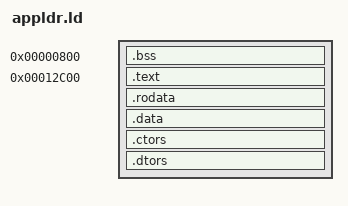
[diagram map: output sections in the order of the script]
ENTRY(_start)

SECTIONS
{
  . = 0x800;

  .bss :
  {
    */appldr/src/loader_global.o(.bss.g_loader)
    */appldr/src/loader.o(.bss.s_unwrapped_keysets)
    */appldr/src/loader.o(.bss.s_unwrapped_keys)
    */appldr/src/loader.o(.bss.s_version)
    */appldr/src/loader.o(.bss.s_version_checked)
    */appldr/src/loader_data.o(.bss.g_qa_flag)
    */appldr/src/loader_data.o(.bss.g_key)
    */appldr/src/loader_data.o(.bss.g_iv)
    */appldr/src/loader_data.o(.bss.g_9b0)
    */appldr/src/loader_data.o(.bss.g_auth_area)
    */appldr/src/loader_data.o(.bss.g_qa_token)
    */appldr/src/loader_data.o(.bss.g_revoke_list)
    */appldr/src/loader_data.o(.bss.g_stream_area)
    */appldr/src/loader_data.o(.bss.g_direct_area)
    */isoldr/src/cipher_aes256_cbc.o(.bss.g_aes256_cbc)
    */isoldr/src/verifier_ecdsa.o(.bss.verify_hash)
    */appldr/src/auth_data.o(.bss.g_revoke_buf)
    */appldr/src/auth_data.o(.bss.g_revoke_digest)
    */lv1ldr/src/auth_buffers.o(.bss.g_part_area)
    */lv1ldr/src/auth_buffers.o(.bss.g_part_digest)
    */appldr/src/auth_data.o(.bss.g_3e40)
    */lv1ldr/src/auth_transfer.o(.bss.g_inf_tail)
    */isoldr/src/hmac_digest.o(.bss.g_hmac)
    */lv1ldr/src/auth_transfer.o(.bss.g_inf_offset)
    */lv1ldr/src/auth_transfer.o(.bss.g_inf_total)
    */lv1ldr/src/auth_transfer.o(.bss.g_inf_out)
    */lv1ldr/src/auth_transfer.o(.bss.g_inf_done)
    */lv1ldr/src/auth_transfer.o(.bss.g_inf_avail)
    */lv1ldr/src/auth_transfer.o(.bss.g_inf_p)
    */appldr/src/mac_aes_cmac.o(.bss.g_mac_aes_cmac)
    */appldr/src/mac_hmac_sha1.o(.bss.g_mac_hmac_sha1)
    */appldr/src/mac_type1.o(.bss.g_mac_type1)
    */appldr/src/cipher_aes128_cbc_chain.o(.bss.g_aes128_cbc_chain)
    */isoldr/src/cipher_aes128_ctr.o(.bss.g_aes128_ctr)
    */appldr/src/cipher_plain.o(.bss.g_plain_cipher)
    */isoldr/src/dma_buffer.o(.bss.g_dma_mfc)
    */lv1ldr/zlib/lv1ldr_inflate.o(.bss.g_strm)
    */lv1ldr/zlib/inflate.o(.bss.lv1ldr_window_used)
    */lv1ldr/zlib/inflate.o(.bss.lv1ldr_state_used)
    */lv1ldr/zlib/inflate.o(.bss.lv1ldr_state)
    */lv1ldr/zlib/inflate.o(.bss.lv1ldr_window)
    *(.bss .bss.* .gnu.linkonce.b.*)
    *(COMMON)
  }

  . = 0x12c00;

  .text :
  {
    */isoldr/src/crt0.o(.text)
    *(.text._ZN6cipher6vslot6EPKv)
    *(.text._ZN6cipher6vslot7EPv)
    *(.text._ZN3mac7restoreEPKv)
    *(.text._ZN3mac4saveEPv)
    *(.text._ZN3mac12set_mac_sizeEj)
    */appldr/src/mac_hmac_sha1.o(.text._ZN13mac_hmac_sha112set_mac_sizeEj)
    *(.text._ZN3macD0Ev)
    *(.text._ZN3macD1Ev)
    *(.text._ZN3macD2Ev)
    */appldr/src/mac_type1.o(.text._ZN9mac_type1D0Ev)
    */appldr/src/mac_type1.o(.text._ZN9mac_type1D1Ev)
    */appldr/src/mac_hmac_sha1.o(.text._ZN13mac_hmac_sha1D0Ev)
    */appldr/src/mac_hmac_sha1.o(.text._ZN13mac_hmac_sha1D1Ev)
    */appldr/src/mac_aes_cmac.o(.text._ZN12mac_aes_cmacD0Ev)
    */appldr/src/mac_aes_cmac.o(.text._ZN12mac_aes_cmacD1Ev)
    *(.text._ZN6cipherD0Ev)
    *(.text._ZN6cipherD1Ev)
    */appldr/src/loader_global.o(.text._Z41__static_initialization_and_destruction_0ii)
    */appldr/src/loader_global.o(.text._GLOBAL__I_g_loader)
    */appldr/src/main.o(.text._Z9stop_withl)
    */appldr/src/main.o(.text.main)
    */lv2ldr/src/auth_checks.o(.text._ZeqRK10auth_flagsS1_)
    */appldr/src/auth_flags.o(.text._ZneRK10auth_flagsS1_)
    */lv2ldr/src/auth_checks.o(.text._ZanRK10auth_flagsS1_)
    */lv2ldr/src/hash_reader.o(.text._Z12bytes_differPKhS0_i)
    */appldr/src/loader.o(.text._ZN6loader14version_numberEy)
    */appldr/src/loader.o(.text._ZN6loader9has_flagsERK10auth_flagsS2_)
    */appldr/src/loader.o(.text._ZN6loader9read_modeEv)
    */appldr/src/loader.o(.text._ZN6loader14override_stateEP10auth_flags)
    */appldr/src/loader.o(.text._ZN6loader14check_type_bitEjPK10auth_flags)
    */appldr/src/loader.o(.text._ZN6loader18keyset_pub_is_zeroEv)
    */appldr/src/loader.o(.text._ZN6loader13check_flags_aEyRK10auth_flagsS2_)
    */appldr/src/loader.o(.text._ZN6loader9is_kind_bEPK13auth_app_infoRK10auth_flagsS5_)
    */appldr/src/loader.o(.text._ZN6loader9is_kind_cEPK13auth_app_infoRK10auth_flagsS5_)
    */appldr/src/loader.o(.text._ZN6loader9is_kind_dEPK13auth_app_infoRK10auth_flagsS5_)
    */appldr/src/loader.o(.text._ZN6loader7unpack3EPKjP10auth_flags)
    */appldr/src/loader.o(.text._ZN6loader7unpack4EPKjP10auth_flags)
    */appldr/src/loader.o(.text._ZN6loader11check_knownERK10auth_flagsS2_PKh)
    */appldr/src/loader.o(.text._ZN6loader8flag_setEv)
    */appldr/src/loader.o(.text._ZN6loader16check_type_valueEjj)
    */appldr/src/loader.o(.text._ZN6loader8lookup_aEtPj)
    */appldr/src/loader.o(.text._ZN6loader8lookup_bEtPj)
    */appldr/src/loader.o(.text._ZN6loader6lookupEjtPj)
    */appldr/src/loader.o(.text._ZN6loader10is_129_130Ejb)
    */appldr/src/loader.o(.text._ZN9key_storeD0Ev)
    */appldr/src/loader.o(.text._ZN9key_storeD1Ev)
    *(.text._ZN9encryptorD0Ev)
    *(.text._ZN9encryptorD1Ev)
    *(.text._ZN9encryptorD2Ev)
    */isoldr/src/aes256_cbc_encryptor.o(.text._ZN20aes256_cbc_encryptorD0Ev)
    *(.text._ZN20aes256_cbc_encryptorD1Ev)
    */appldr/src/segment_loader.o(.text._ZN14segment_loaderD0Ev)
    */appldr/src/segment_loader.o(.text._ZN14segment_loaderD1Ev)
    */appldr/src/loader.o(.text._ZN9key_store7requestEv)
    */appldr/src/loader.o(.text._ZN9key_store11unwrap_keysEv)
    */appldr/src/loader.o(.text._ZN9key_store14unwrap_keysetsEv)
    */appldr/src/loader.o(.text._ZN9key_store13check_versionEy)
    */appldr/src/loader.o(.text._ZN6loader17check_old_versionEP13authenticator)
    */appldr/src/loader.o(.text._ZN6loader5fetchEyPv)
    */appldr/src/loader.o(.text._ZN6loader12read_requestEv)
    */appldr/src/loader.o(.text._ZN6loader10put_resultEv)
    */appldr/src/loader.o(.text._ZN6loader10get_digestEPhj)
    */appldr/src/loader.o(.text._ZN6loader19check_version_limitEyP13authenticator)
    *(.text._ZN17tagged_dma_bufferD1Ev)
    */appldr/src/loader.o(.text._ZN6loader10check_hashEv)
    */appldr/src/loader.o(.text._ZN6loader20check_control_digestEP13authenticator)
    */appldr/src/loader.o(.text._ZN6loader9get_stateEP13authenticatorP10auth_flags)
    */appldr/src/loader.o(.text._ZN6loader10put_answerEP13authenticatorPK8app_args)
    */appldr/src/loader.o(.text._ZN6loader10check_kindEv)
    */appldr/src/loader.o(.text._ZN6loader11check_stateEjP13authenticatorP10auth_flags)
    */appldr/src/loader.o(.text._ZN6loader12decrypt_argsEPKh)
    */appldr/src/loader.o(.text._ZN6loader13pick_args_keyEtbP10keyset_ref)
    */appldr/src/loader.o(.text._ZN6loader11find_keysetEjjtjbP10keyset_ref)
    */appldr/src/loader.o(.text._ZN6loader12read_qa_flagEjPKhPK8qa_tokenPhS5_)
    */appldr/src/loader.o(.text._ZN6loader11open_paramsEPjPh)
    */appldr/src/loader.o(.text._ZN6loader6load_bEv)
    */appldr/src/loader.o(.text._ZN6loader9read_typeEPjP13authenticator)
    */appldr/src/loader.o(.text._ZN6loader14section_extentEjjPyS0_)
    */appldr/src/loader.o(.text._ZN6loader12load_sectionEv)
    */appldr/src/loader.o(.text._ZN6loader17check_revoke_listEP11revoke_listPKv)
    */appldr/src/loader.o(.text._ZN6loader7prepareEv)
    */appldr/src/loader.o(.text._ZN6loader10load_imageEjP13authenticatorPK10keyset_refj)
    */appldr/src/loader.o(.text._ZN6loader13check_revokedEjP11revoke_listP13authenticator)
    */appldr/src/loader.o(.text._ZN6loader11check_imageEv)
    */appldr/src/loader.o(.text._ZN6loader5resetEv)
    */appldr/src/loader.o(.text._ZN6loader10open_imageEv)
    */appldr/src/loader.o(.text._ZN6loader6load_aEv)
    */appldr/src/loader.o(.text._ZN6loaderC1Ev)
    */appldr/src/loader.o(.text._ZN6loaderC2Ev)
    */appldr/src/loader.o(.text._ZN6loader3runEv)
    */isoldr/src/hmac_digest.o(.text._ZN11hmac_digestC2Ev)
    */isoldr/src/hmac_digest.o(.text._ZN11hmac_digestC1Ev)
    */isoldr/src/qa_flag.o(.text._ZN14qa_flag_reader4initEv)
    *(.text._ZN6cipherD2Ev)
    */isoldr/src/cipher_aes256_cbc.o(.text._ZN17aes256_cbc_cipherD0Ev)
    *(.text._ZN17aes256_cbc_cipherD1Ev)
    *(.text._ZN8verifierD0Ev)
    *(.text._ZN8verifierD1Ev)
    *(.text._ZN8verifierD2Ev)
    */isoldr/src/verifier_ecdsa.o(.text._ZN14ecdsa_verifierD0Ev)
    *(.text._ZN14ecdsa_verifierD1Ev)
    */isoldr/src/qa_flag.o(.text._ZN14qa_flag_reader5checkEjPKhPhS1_S1_)
    */appldr/src/segment_loader.o(.text._ZN13direct_loaderC1Ev)
    */appldr/src/segment_loader.o(.text._ZN13direct_loaderC2Ev)
    */appldr/src/segment_loader.o(.text._ZN13direct_loader4openEP13authenticatorj)
    */appldr/src/segment_loader.o(.text._ZN13direct_loader5closeEv)
    */appldr/src/segment_loader.o(.text._ZN14segment_loaderD2Ev)
    */appldr/src/segment_loader.o(.text._ZN13direct_loaderD0Ev)
    */appldr/src/segment_loader.o(.text._ZN13direct_loaderD1Ev)
    */appldr/src/segment_loader.o(.text._ZN13direct_loader4loadEyyyyPP10dma_bufferjS2_j)
    */appldr/src/segment_loader.o(.text._ZN13stream_loaderC1Ev)
    */appldr/src/segment_loader.o(.text._ZN13stream_loaderC2Ev)
    */appldr/src/segment_loader.o(.text._ZN13stream_loader4openEP13authenticatorj)
    */appldr/src/segment_loader.o(.text._ZN13stream_loader5closeEv)
    */appldr/src/segment_loader.o(.text._ZN13stream_loaderD0Ev)
    */appldr/src/segment_loader.o(.text._ZN13stream_loaderD1Ev)
    */appldr/src/segment_loader.o(.text._ZN13stream_loader6notifyEj)
    */appldr/src/segment_loader.o(.text._ZN13stream_loader10wait_readyEv)
    */appldr/src/segment_loader.o(.text._ZN13stream_loader10next_blockEP12stream_block)
    */appldr/src/segment_loader.o(.text._ZN13stream_loader4loadEyyyyPP10dma_bufferjS2_j)
    */appldr/src/hash_verify.o(.text._ZN11hash_reader6verifyEPKhj)
    */lv2ldr/src/hash_reader.o(.text._ZN11hash_reader4openEyyPP10dma_bufferjPKhj)
    *(.text._ZN11hash_readerD0Ev)
    *(.text._ZN11hash_readerD1Ev)
    */lv2ldr/src/hash_reader.o(.text._ZN11hash_readerC1Ev)
    */lv2ldr/src/hash_reader.o(.text._ZN11hash_readerC2Ev)
    */lv2ldr/src/hash_reader.o(.text._ZN11hash_reader4readEv)
    *(.text._ZN17aes256_cbc_cipherC1Ev)
    */isoldr/src/cipher_aes256_cbc.o(.text._Z41__static_initialization_and_destruction_0ii)
    */isoldr/src/cipher_aes256_cbc.o(.text._GLOBAL__D_g_aes256_cbc)
    */isoldr/src/cipher_aes256_cbc.o(.text._GLOBAL__I_g_aes256_cbc)
    */isoldr/src/cipher_aes256_cbc.o(.text._ZN17aes256_cbc_cipher7decryptEPKviPv)
    */isoldr/src/cipher_aes256_cbc.o(.text._ZN17aes256_cbc_cipher7set_keyEPKhS1_)
    */appldr/src/loader.o(.text._ZN20aes256_cbc_encryptorC1Ev)
    */isoldr/src/aes256_cbc_encryptor.o(.text._ZN20aes256_cbc_encryptor7set_keyEPKhPK9cipher_iv)
    */isoldr/src/aes256_cbc_encryptor.o(.text._ZN20aes256_cbc_encryptor7encryptEPKviPv)
    */lv2ldr/src/auth_checks.o(.text._ZN13authenticator19check_auth_id_classEyy)
    */lv2ldr/src/auth_checks.o(.text._ZN13authenticator18has_required_flagsEv)
    */lv2ldr/src/auth_checks.o(.text._ZN13authenticator12check_issuerEyy)
    */appldr/src/auth_app.o(.text._ZN13authenticator10set_headerEjPKv)
    */lv1ldr/src/auth_buffers.o(.text._ZN13authenticator17check_part_digestEPK12auth_section)
    */appldr/src/auth_app_checks.o(.text._ZN13authenticator20check_section_digestEv)
    */isoldr/src/verifier_ecdsa.o(.text._ZN14ecdsa_verifier6verifyEPKhiS1_)
    */isoldr/src/verifier_ecdsa.o(.text._ZN14ecdsa_verifierC1EPKhj)
    */isoldr/src/verifier_ecdsa.o(.text._ZN14ecdsa_verifierC2EPKhj)
    */lv2ldr/src/auth_checks.o(.text._ZN13authenticator9get_stateEPy)
    */lv2ldr/src/auth_checks.o(.text._ZN13authenticator12get_app_infoEP13auth_app_info)
    */appldr/src/auth_app_checks.o(.text._ZN13authenticator16get_section_infoEjPv)
    */appldr/src/auth_app_checks.o(.text._ZN13authenticator18get_control_digestEPh)
    */lv1ldr/src/loader_params.o(.text._ZN11param_block4initEv)
    */lv1ldr/src/loader_params.o(.text._ZN11param_block4openEPKhjS1_S1_S1_S1_PjPhS3_)
    */appldr/src/auth_app_checks.o(.text._ZN13authenticator8is_elf64Ev)
    */appldr/src/auth_app_checks.o(.text._ZN13authenticator8is_elf32Ev)
    */appldr/src/auth_app_checks.o(.text._ZN13authenticator8flag_1b9Ev)
    */lv2ldr/src/auth_checks.o(.text._ZN10auth_state3getEPy)
    */lv1ldr/src/auth_buffers.o(.text._ZN10auth_state4loadEPK10auth_entryy)
    */lv1ldr/src/auth_buffers.o(.text._ZN10auth_stateC1Ev)
    */lv1ldr/src/auth_buffers.o(.text._ZN10auth_stateC2Ev)
    */lv2ldr/src/revoke_list.o(.text._ZN11revoke_list4initEv)
    */lv2ldr/src/revoke_list.o(.text._ZN11revoke_list12check_headerEPK18revoke_list_header)
    */lv2ldr/src/revoke_list.o(.text._ZN11revoke_list13check_versionEy)
    */isoldr/src/cipher_aes128_ctr.o(.text._ZN17aes128_ctr_cipherD0Ev)
    */isoldr/src/cipher_aes128_ctr.o(.text._ZN17aes128_ctr_cipherD1Ev)
    */lv2ldr/src/revoke_list.o(.text._ZN11revoke_list15check_encryptedEPK12auth_section)
    */lv2ldr/src/revoke_list.o(.text._ZN11revoke_list11check_plainEPK12auth_section)
    */lv2ldr/src/revoke_list.o(.text._ZN11revoke_list5parseEv)
    */lv2ldr/src/revoke_list.o(.text._ZN11revoke_list4openEPKhS1_S1_PKj)
    */lv2ldr/src/revoke_list.o(.text._ZN11revoke_list4loadEPKv)
    */lv1ldr/src/authenticator.o(.text._ZN9elf_imageC1Ev)
    */lv1ldr/src/authenticator.o(.text._ZN9elf_image4loadEPKv)
    */lv1ldr/src/authenticator.o(.text._ZN13authenticator10set_offsetEy)
    */lv1ldr/src/authenticator.o(.text._ZN13authenticator14check_app_infoEPK13auth_app_infoj)
    */lv1ldr/src/authenticator.o(.text._ZN13authenticator9check_appEP9sce_imagej)
    */lv1ldr/src/authenticator.o(.text._ZN13authenticator11clear_partsEv)
    */lv1ldr/src/authenticator.o(.text._ZN13authenticatorC1Ev)
    */lv1ldr/src/authenticator.o(.text._ZN13authenticatorC2Ev)
    */appldr/src/auth_app.o(.text._ZN13authenticator5resetEv)
    */lv1ldr/src/authenticator.o(.text._ZN13authenticator19read_program_headerEjP10Elf64_Phdr)
    */lv1ldr/src/authenticator.o(.text._ZN13authenticator15read_elf_headerEP10Elf64_Ehdr)
    */isoldr/src/elf_reader32.o(.text._ZN13authenticator19read_program_headerEjP10Elf32_Phdr)
    */isoldr/src/elf_reader32.o(.text._ZN13authenticator15read_elf_headerEP10Elf32_Ehdr)
    */appldr/src/auth_app.o(.text._ZN13authenticator14select_sectionEjj)
    */appldr/src/auth_app.o(.text._ZN10auth_block5get_wEPy)
    */appldr/src/auth_app.o(.text._ZN10auth_block10get_digestEPh)
    */lv1ldr/src/authenticator.o(.text._ZN10auth_block3getEPy)
    */lv1ldr/src/auth_buffers.o(.text._ZN10auth_block4loadEPK10auth_entryy)
    */lv1ldr/src/auth_buffers.o(.text._ZN10auth_blockC1Ev)
    */lv1ldr/src/auth_buffers.o(.text._ZN10auth_blockC2Ev)
    */isoldr/src/hmac_digest.o(.text._Z41__static_initialization_and_destruction_0ii)
    */isoldr/src/hmac_digest.o(.text._GLOBAL__I_g_hmac)
    */isoldr/src/hmac_digest.o(.text._GLOBAL__D_g_hmac)
    */isoldr/src/hmac_digest.o(.text._ZN11hmac_digest6updateEPKhi)
    */isoldr/src/hmac_digest.o(.text._ZN11hmac_digest5finalEPh)
    */isoldr/src/hmac_digest.o(.text._ZN11hmac_digest4initEPKhj)
    */isoldr/src/hmac_digest.o(.text._ZN11hmac_digest6digestEPKhiPhS1_j)
    */lv2ldr/src/revoke_check.o(.text._ZN11revoke_list10is_revokedEjyy)
    */appldr/src/cipher_aes128_cbc_chain.o(.text._ZN23aes128_cbc_chain_cipherD0Ev)
    */appldr/src/cipher_aes128_cbc_chain.o(.text._ZN23aes128_cbc_chain_cipherD1Ev)
    */appldr/src/auth_app.o(.text._ZN13authenticator11load_headerEjPKhS1_S1_PKjPP10dma_bufferjPvS1_b)
    */appldr/src/auth_app.o(.text._ZN11header_data7decryptEv)
    */lv1ldr/src/auth_buffers.o(.text._ZN11header_data5clearEv)
    */appldr/src/auth_app.o(.text._ZN9auth_tail5resetEv)
    */lv1ldr/src/auth_buffers.o(.text._ZN9auth_tailC1Ev)
    */lv1ldr/src/auth_buffers.o(.text._ZN9auth_tailC2Ev)
    */appldr/src/auth_app.o(.text._ZN11header_data4hashEv)
    */appldr/src/auth_app.o(.text._ZN11header_data7restoreEPK10dma_buffer)
    */appldr/src/auth_app.o(.text._ZN11header_data7prependEPK10dma_bufferj)
    */appldr/src/auth_app.o(.text._ZN11header_data4saveEPK10dma_buffer)
    */appldr/src/auth_app_transfer.o(.text._ZN13authenticator16transfer_segmentEyyyyPP10dma_bufferjS2_jPy)
    */appldr/src/auth_app_transfer.o(.text._ZN13authenticator17transfer_deflatedEybbPy)
    */appldr/src/auth_app_transfer.o(.text._ZN13authenticator15transfer_storedEbbPy)
    */lv1ldr/src/auth_transfer.o(.text._ZN13authenticator13inflate_pieceEP10dma_bufferyPy)
    */appldr/src/auth_app_transfer.o(.text._ZN13authenticator7requeueEP10dma_bufferS1_RKbS3_Py)
    */appldr/src/data_decryptor.o(.text._ZN14data_decryptor5resetEv)
    */appldr/src/data_decryptor.o(.text._ZN14data_decryptor10set_cipherEj)
    */appldr/src/data_decryptor.o(.text._ZN14data_decryptor7set_macEj)
    */appldr/src/data_decryptor.o(.text._ZN14data_decryptor5checkEjjj)
    */appldr/src/data_decryptor.o(.text._ZN14data_decryptor7restoreEPK15decryptor_state)
    */appldr/src/cipher_plain.o(.text._ZN12plain_cipherD0Ev)
    */appldr/src/cipher_plain.o(.text._ZN12plain_cipherD1Ev)
    */appldr/src/data_decryptor.o(.text._ZN14data_decryptor4saveEP15decryptor_state)
    */appldr/src/data_decryptor.o(.text._ZN14data_decryptor14derive_mac_keyEPKhPhjj)
    */appldr/src/data_decryptor.o(.text._ZN14data_decryptor10derive_keyEPKhS1_PhS2_jj)
    */appldr/src/data_decryptor.o(.text._ZN14data_decryptor10state_keysEPhS0_)
    */appldr/src/data_decryptor.o(.text._ZN14data_decryptor4sealEPh)
    */appldr/src/data_decryptor.o(.text._ZN14data_decryptor6unsealEPh)
    */appldr/src/data_decryptor.o(.text._ZN14data_decryptor9put_stateEyPKh)
    */appldr/src/data_decryptor.o(.text._ZN14data_decryptor9get_stateEyPh)
    */appldr/src/data_decryptor.o(.text._ZN14data_decryptor6finishEyy)
    */appldr/src/data_decryptor.o(.text._ZN14data_decryptor4pumpEv)
    */appldr/src/data_decryptor.o(.text._ZN14data_decryptor7processEyyyPP10dma_bufferjS2_j)
    */appldr/src/data_decryptor.o(.text._ZN14data_decryptorC1Ev)
    */appldr/src/data_decryptor.o(.text._ZN14data_decryptorC2Ev)
    */appldr/src/data_decryptor.o(.text._ZN14data_decryptor4openEPKhS1_S1_jjyj)
    */appldr/src/data_decryptor.o(.text._ZN14data_decryptor7requeueEP10dma_bufferS1_)
    */appldr/src/mac_aes_cmac.o(.text._ZN12mac_aes_cmacC1Ev)
    */appldr/src/mac_aes_cmac.o(.text._ZN12mac_aes_cmacC2Ev)
    */appldr/src/mac_aes_cmac.o(.text._Z41__static_initialization_and_destruction_0ii)
    */appldr/src/mac_aes_cmac.o(.text._GLOBAL__D_g_mac_aes_cmac)
    */appldr/src/mac_aes_cmac.o(.text._GLOBAL__I_g_mac_aes_cmac)
    */appldr/src/mac_aes_cmac.o(.text._ZN12mac_aes_cmac4saveEPv)
    */appldr/src/mac_aes_cmac.o(.text._ZN12mac_aes_cmac7restoreEPKv)
    */appldr/src/mac_aes_cmac.o(.text._ZN12mac_aes_cmac4initEPKhj)
    */appldr/src/mac_aes_cmac.o(.text._ZN12mac_aes_cmac6updateEPKvj)
    */appldr/src/mac_aes_cmac.o(.text._ZN12mac_aes_cmac6verifyEPKh)
    */appldr/src/mac_hmac_sha1.o(.text._ZN13mac_hmac_sha1C2Ev)
    */appldr/src/mac_hmac_sha1.o(.text._ZN13mac_hmac_sha1C1Ev)
    */appldr/src/mac_hmac_sha1.o(.text._ZN13mac_hmac_sha17restoreEPKv)
    */appldr/src/mac_hmac_sha1.o(.text._ZN13mac_hmac_sha14saveEPv)
    */appldr/src/mac_hmac_sha1.o(.text._Z41__static_initialization_and_destruction_0ii)
    */appldr/src/mac_hmac_sha1.o(.text._GLOBAL__D_g_mac_hmac_sha1)
    */appldr/src/mac_hmac_sha1.o(.text._GLOBAL__I_g_mac_hmac_sha1)
    */appldr/src/mac_hmac_sha1.o(.text._ZN13mac_hmac_sha16updateEPKvj)
    */appldr/src/mac_hmac_sha1.o(.text._ZN13mac_hmac_sha16verifyEPKh)
    */appldr/src/mac_hmac_sha1.o(.text._ZN13mac_hmac_sha14initEPKhj)
    */appldr/src/mac_type1.o(.text._ZN9mac_type1C1Ev)
    */appldr/src/mac_type1.o(.text._ZN9mac_type1C2Ev)
    */appldr/src/mac_type1.o(.text._ZN9mac_type14initEPKhj)
    */appldr/src/mac_type1.o(.text._ZN9mac_type16verifyEPKh)
    */appldr/src/mac_type1.o(.text._ZN9mac_type16updateEPKvj)
    */appldr/src/mac_type1.o(.text._Z41__static_initialization_and_destruction_0ii)
    */appldr/src/mac_type1.o(.text._GLOBAL__D_g_mac_type1)
    */appldr/src/mac_type1.o(.text._GLOBAL__I_g_mac_type1)
    */appldr/src/auth_app_control.o(.text._ZN13authenticator13get_control_wEPy)
    */appldr/src/auth_app_control.o(.text._ZN13authenticator18get_control_valuesEPy)
    */appldr/src/auth_app_control.o(.text._ZN13authenticator18get_section_digestEjjPhj)
    */appldr/src/auth_app_control.o(.text._ZN13authenticator10build_metaEP9sce_imageP9auth_meta)
    */appldr/src/cipher_aes128_cbc_chain.o(.text._ZN23aes128_cbc_chain_cipher6vslot7EPv)
    */appldr/src/cipher_aes128_cbc_chain.o(.text._ZN23aes128_cbc_chain_cipher6vslot6EPKv)
    */appldr/src/cipher_aes128_cbc_chain.o(.text._ZN23aes128_cbc_chain_cipher7decryptEPKviPv)
    */appldr/src/cipher_aes128_cbc_chain.o(.text._ZN23aes128_cbc_chain_cipher7set_keyEPKhS1_)
    */appldr/src/cipher_aes128_cbc_chain.o(.text._ZN23aes128_cbc_chain_cipherC1Ev)
    */appldr/src/cipher_aes128_cbc_chain.o(.text._Z41__static_initialization_and_destruction_0ii)
    */appldr/src/cipher_aes128_cbc_chain.o(.text._GLOBAL__D_g_aes128_cbc_chain)
    */appldr/src/cipher_aes128_cbc_chain.o(.text._GLOBAL__I_g_aes128_cbc_chain)
    */isoldr/src/cipher_aes128_ctr.o(.text._ZN17aes128_ctr_cipherC1Ev)
    */isoldr/src/cipher_aes128_ctr.o(.text._Z41__static_initialization_and_destruction_0ii)
    */isoldr/src/cipher_aes128_ctr.o(.text._GLOBAL__D_g_aes128_ctr)
    */isoldr/src/cipher_aes128_ctr.o(.text._GLOBAL__I_g_aes128_ctr)
    */isoldr/src/cipher_aes128_ctr.o(.text._ZN17aes128_ctr_cipher7decryptEPKviPv)
    */isoldr/src/cipher_aes128_ctr.o(.text._ZN17aes128_ctr_cipher7set_keyEPKhS1_)
    */appldr/src/cipher_plain.o(.text._ZN12plain_cipher7set_keyEPKhS1_)
    */appldr/src/cipher_plain.o(.text._ZN12plain_cipher6vslot6EPKv)
    */appldr/src/cipher_plain.o(.text._ZN12plain_cipher6vslot7EPv)
    */appldr/src/cipher_plain.o(.text._ZN12plain_cipher7decryptEPKviPv)
    */appldr/src/cipher_plain.o(.text._Z41__static_initialization_and_destruction_0ii)
    */appldr/src/cipher_plain.o(.text._GLOBAL__D_g_plain_cipher)
    */appldr/src/cipher_plain.o(.text._GLOBAL__I_g_plain_cipher)
    */lv1ldr/src/auth_buffers.o(.text._ZN9auth_sink6appendEPKU8__vectorhS2_)
    */lv1ldr/src/auth_buffers.o(.text._ZN13authenticator10read_partsEv)
    */lv1ldr/src/auth_buffers.o(.text._ZN13authenticator12find_sectionEjjP12auth_section)
    */lv1ldr/src/elf_reader.o(.text._ZN9elf_image10get_headerEP10Elf64_Ehdr)
    */lv1ldr/src/elf_reader.o(.text._ZN9elf_image18get_program_headerEjP10Elf64_Phdr)
    */isoldr/src/elf_reader32.o(.text._ZN9elf_image10get_headerEP10Elf32_Ehdr)
    */isoldr/src/elf_reader32.o(.text._ZN9elf_image18get_program_headerEjP10Elf32_Phdr)
    */lv2ldr/src/revoke_scan.o(.text._ZN11revoke_list10scan_pairsEyy)
    */lv2ldr/src/revoke_scan.o(.text._ZN11revoke_list11scan_pairs2Eyy)
    */lv2ldr/src/revoke_scan.o(.text._ZN11revoke_list10scan_rulesEjyy)
    */isoldr/src/dma_queue.o(.text._ZN9dma_queue12enqueue_readEP10dma_buffer)
    */isoldr/src/dma_queue.o(.text._ZN9dma_queue7dequeueEPP10dma_bufferP9list_nodeMS0_FbvE)
    */isoldr/src/dma_queue.o(.text._ZN9dma_queue12dequeue_readEPP10dma_buffer)
    */isoldr/src/dma_queue.o(.text._ZN9dma_queue5drainEP9list_nodeM10dma_bufferFbvE)
    */isoldr/src/dma_queue.o(.text._ZN9dma_queue5closeEv)
    */isoldr/src/dma_queue.o(.text._ZN9dma_queueC2Ev)
    */isoldr/src/dma_queue.o(.text._ZN9dma_queueC1Ev)
    */isoldr/src/dma_queue.o(.text._ZN9dma_queue11add_writtenEP10dma_buffer)
    */isoldr/src/dma_queue.o(.text._ZN9dma_queue13enqueue_writeEP10dma_buffer)
    */isoldr/src/dma_queue.o(.text._ZN9dma_queue13dequeue_writeEPP10dma_buffer)
    */isoldr/src/dma_queue.o(.text._ZN9dma_queue4openEyjyj)
    */isoldr/src/dma_buffer.o(.text._ZN10dma_buffer10set_bufferEjj)
    *(.text._ZN10dma_bufferD0Ev)
    *(.text._ZN10dma_bufferD1Ev)
    *(.text._ZN10dma_bufferD2Ev)
    */isoldr/src/dma_buffer.o(.text._ZN10dma_bufferC2Ev)
    */isoldr/src/dma_buffer.o(.text._ZN10dma_bufferC1Ev)
    */isoldr/src/dma_buffer.o(.text._ZN17tagged_dma_buffer9max_chunkEj)
    */isoldr/src/dma_buffer_io.o(.text._ZN17tagged_dma_bufferD0Ev)
    */isoldr/src/dma_buffer.o(.text._ZN7dma_mfcC1Ev)
    */isoldr/src/dma_buffer.o(.text._Z41__static_initialization_and_destruction_0ii)
    */isoldr/src/dma_buffer.o(.text._GLOBAL__I__ZN10dma_bufferC2Ev)
    */isoldr/src/dma_buffer.o(.text._ZN17tagged_dma_buffer8transferEyyjj)
    */isoldr/src/dma_buffer.o(.text._ZN17tagged_dma_buffer8put_doneEv)
    */isoldr/src/dma_buffer.o(.text._ZN17tagged_dma_buffer8get_doneEv)
    */isoldr/src/dma_buffer.o(.text._ZN17tagged_dma_bufferC2Ej)
    */isoldr/src/dma_buffer.o(.text._ZN17tagged_dma_bufferC1Ej)
    */isoldr/src/dma_buffer_io.o(.text._ZN17tagged_dma_buffer3putEyjPj)
    */isoldr/src/dma_buffer_io.o(.text._ZN17tagged_dma_buffer3getEyjPj)
    */lv0ldr/crypto/aes_set_encrypt_key.o(.text)
    */lv0ldr/crypto/aes_set_decrypt_key.o(.text)
    */lv0ldr/crypto/aes_encrypt_block.o(.text)
    */lv0ldr/crypto/aes_decrypt_block.o(.text)
    */lv0ldr/crypto/aes_cbc_encrypt.o(.text)
    */lv0ldr/crypto/aes_modes.o(.text)
    */isoldr/crypto/aes_cmac.o(.text)
    */lv0ldr/crypto/sha1_digest.o(.text)
    */lv0ldr/crypto/hmac_sha1.o(.text)
    */isoldr/crypto/hmac_sha1_once.o(.text)
    */lv0ldr/crypto/aes_encrypt8.o(.text)
    */lv0ldr/crypto/aes_decrypt8.o(.text)
    */lv0ldr/crypto/sha1.o(.text)
    */lv0ldr/crypto/sha1_transform.o(.text)
    */isoldr/crypto/ecdsa.o(.text)
    */lv0ldr/crypto/ec.o(.text)
    */lv0ldr/crypto/ec_mul2.o(.text)
    */lv0ldr/crypto/bn_core.o(.text)
    */lv0ldr/crypto/bn_in_range.o(.text)
    */lv0ldr/crypto/ec_curve_valid.o(.text)
    */lv0ldr/crypto/ecdsa_id.o(.text)
    */lv0ldr/crypto/ec_curves.o(.text)
    */lv0ldr/crypto/bn_from_bytes_not.o(.text)
    */isoldr/src/mfc.o(.text._ZN8mfc_baseC2Ev)
    */isoldr/src/mfc.o(.text._ZN8mfc_baseC1Ev)
    */isoldr/src/mfc.o(.text._Z9mfc_issuejyjjjj)
    */isoldr/src/mfc.o(.text._Z12mfc_tag_donej)
    */appldr/src/mfc_ext.o(.text._Z17mfc_atomic_statusv)
    */appldr/src/mfc_ext.o(.text._Z10ll_getllarjy)
    */appldr/src/mfc_ext.o(.text._Z9ll_putllcjy)
    */appldr/src/mfc_ext.o(.text._Z12event_statusPj)
    */appldr/src/mfc_ext.o(.text._Z10event_maskj)
    */appldr/src/mfc_ext.o(.text._Z9event_ackj)
    */isoldr/src/mfc.o(.text._Z19mbox_out_intr_writej)
    */appldr/src/mfc_atomic.o(.text._Z7dma_putyPvPKvj)
    */appldr/src/mfc_atomic.o(.text._Z7dma_getyPvS_j)
    */appldr/src/mfc_atomic.o(.text._Z10atomic_getyPv)
    */appldr/src/mfc_atomic.o(.text._Z10atomic_putyPvPKvjj)
    */lv0ldr/src/util/cxx_runtime.o(.text._ZdlPv)
    */lv0ldr/src/util/cxx_runtime.o(.text.__cxa_pure_virtual)
    */isoldr/src/ch64.o(.text._Z12ch64_requestv)
    */lv2ldr/src/ch72.o(.text._Z8ch72_getiPji)
    */lv2ldr/src/ch72.o(.text._Z14ch72_get_replyPh)
    */lv2ldr/src/ch72.o(.text._Z16ch72_get_versionPy)
    */lv2ldr/src/ch72.o(.text._Z20ch72_compare_versiony)
    */lv2ldr/src/ch72.o(.text._Z11ch72_unwrapPU8__vectorhPKS_iPKhiS2_)
    */lv2ldr/src/ch72.o(.text._Z14ch72_unwrap_ivPU8__vectorhPKS_i)
    */lv2ldr/src/ch72.o(.text._Z15ch72_unwrap_keyPU8__vectorhPKS_i)
    */lv1ldr/src/auth_header.o(.text._ZN9sce_image12get_sectionsEv)
    */lv1ldr/src/auth_header.o(.text._ZN9sce_image17get_section_countEPj)
    */lv1ldr/src/auth_header.o(.text._ZN9sce_image13get_key_countEPj)
    */lv1ldr/src/auth_header.o(.text._ZN9sce_image14get_ext_headerEPjS0_)
    */lv1ldr/src/auth_check.o(.text._Z16check_sce_headerPKU8__vectorhPKvtj)
    */lv1ldr/src/auth_check.o(.text._Z17check_meta_headerPKU8__vectorhPK9auth_metaj)
    */lv1ldr/src/auth_check.o(.text._Z14check_sectionsP9sce_image)
    */lv1ldr/src/auth_check.o(.text._Z18check_control_infoPK12auth_controly)
    */lv1ldr/src/auth_check.o(.text._Z16check_ext_headerP9sce_image)
    */lv1ldr/src/auth_check.o(.text._ZN9sce_image12get_app_infoEPj)
    */lv1ldr/zlib/lv1ldr_inflate.o(.text.lv1ldr_inflate_end)
    */lv1ldr/zlib/lv1ldr_inflate.o(.text.lv1ldr_inflate_init)
    */lv1ldr/zlib/lv1ldr_inflate.o(.text.lv1ldr_inflate)
    */lv1ldr/zlib/inflate.o(.text.inflateEnd)
    */lv1ldr/zlib/inflate.o(.text.updatewindow)
    */lv1ldr/zlib/inflate.o(.text.inflate)
    */lv1ldr/zlib/inflate.o(.text.inflateInit_)
    */lv1ldr/zlib/inftrees.o(.text.inflate_table)
    */lv1ldr/zlib/adler32.o(.text.adler32)
    */lv1ldr/zlib/zutil.o(.text.zcfree)
    */lv1ldr/zlib/zutil.o(.text.zcalloc)
    */lv1ldr/zlib/inffast.o(.text.inflate_fast)
    */lv0ldr/libgcc/muldi3.o(.text)
    */lv0ldr/libgcc/umoddi3.o(.text)
    */lv0ldr/src/boot/exit.o(.text.exit)
    */lv1ldr/src/abort.o(.text.abort)
    */lv0ldr/src/util/memcmp.o(.text.memcmp)
    */isoldr/src/memset.o(.text.memset)
    */isoldr/src/memcpy.o(.text.memcpy)
    *(.text .text.* .gnu.linkonce.t.*)
  }

  .rodata :
  {
    */appldr/src/mac_type1.o(.rodata._ZTV9mac_type1)
    */appldr/src/mac_hmac_sha1.o(.rodata._ZTV13mac_hmac_sha1)
    */appldr/src/mac_aes_cmac.o(.rodata._ZTV12mac_aes_cmac)
    *(.rodata._ZTV3mac)
    *(.rodata._ZTV6cipher)
    */appldr/src/loader.o(.rodata.cst16)
    */appldr/src/loader.o(.rodata._ZTV9key_store)
    */isoldr/src/aes256_cbc_encryptor.o(.rodata._ZTV20aes256_cbc_encryptor)
    *(.rodata._ZTV9encryptor)
    */appldr/src/segment_loader.o(.rodata._ZTV14segment_loader)
    */appldr/src/loader_data.o(.rodata.g_table_a)
    */appldr/src/loader_data.o(.rodata.g_table_b)
    */appldr/src/loader_data.o(.rodata.g_args_key_a)
    */appldr/src/loader_data.o(.rodata.g_args_iv_a)
    */appldr/src/loader_data.o(.rodata.g_args_key_b)
    */appldr/src/loader_data.o(.rodata.g_args_iv_b)
    */appldr/src/loader_data.o(.rodata.g_ref_2e840)
    */appldr/src/loader_data.o(.rodata.g_flags_none)
    */appldr/src/loader_data.o(.rodata.g_flags_1)
    */appldr/src/loader_data.o(.rodata.g_flags_2)
    */appldr/src/loader_data.o(.rodata.g_flags_3)
    */appldr/src/loader_data.o(.rodata.g_flags_4)
    */appldr/src/loader_data.o(.rodata.g_flags_5)
    */appldr/src/loader_data.o(.rodata.g_known_apps)
    */appldr/src/loader_data.o(.rodata.g_flags_old)
    */appldr/src/loader_data.o(.rodata.g_hash_key)
    */appldr/src/loader_data.o(.rodata.g_ref_33f20)
    */appldr/src/loader_data.o(.rodata.g_ref_33f30)
    */appldr/src/loader_data.o(.rodata.params_wrap_0)
    */appldr/src/loader_data.o(.rodata.params_wrap_1)
    */appldr/src/loader_data.o(.rodata.g_list_pub)
    */appldr/src/loader_data.o(.rodata.g_list_curve)
    */isoldr/src/cipher_aes256_cbc.o(.rodata._ZTV17aes256_cbc_cipher)
    */isoldr/src/verifier_ecdsa.o(.rodata._ZTV14ecdsa_verifier)
    *(.rodata._ZTV8verifier)
    */isoldr/src/qa_flag_data.o(.rodata.qa_flag_pub)
    */appldr/src/segment_loader.o(.rodata._ZTV13direct_loader)
    */appldr/src/segment_loader.o(.rodata.cst16)
    */appldr/src/segment_loader.o(.rodata._ZTV13stream_loader)
    *(.rodata._ZTV11hash_reader)
    */lv2ldr/src/auth_checks.o(.rodata.cst16)
    */appldr/src/auth_data.o(.rodata.g_required_flags)
    */appldr/src/auth_data.o(.rodata.params_seed)
    */lv1ldr/src/auth_buffers.o(.rodata.cst16)
    */lv2ldr/src/revoke_list.o(.rodata.cst16)
    */isoldr/src/cipher_aes128_ctr.o(.rodata._ZTV17aes128_ctr_cipher)
    */appldr/src/auth_app.o(.rodata.cst16)
    */appldr/src/cipher_aes128_cbc_chain.o(.rodata._ZTV23aes128_cbc_chain_cipher)
    */appldr/src/cipher_plain.o(.rodata._ZTV12plain_cipher)
    */appldr/src/decryptor_data.o(.rodata.g_state_seed_a)
    */appldr/src/decryptor_data.o(.rodata.g_state_seed_b)
    */appldr/src/decryptor_data.o(.rodata.g_key_ivs)
    */appldr/src/auth_app_control.o(.rodata.cst16)
    *(.rodata._ZTV10dma_buffer)
    */isoldr/src/dma_buffer_io.o(.rodata._ZTV17tagged_dma_buffer)
    */crypto/*.o(.rodata .rodata.*)
    */appldr/src/auth_data.o(.rodata.ch72_key_data)
    */appldr/src/auth_data.o(.rodata.ch72_iv_data)
    */appldr/src/auth_data.o(.rodata.ch72_key_iv)
    */appldr/src/auth_data.o(.rodata.ch72_iv_iv)
    */appldr/src/auth_data.o(.rodata.key_slots)
    */appldr/src/auth_data.o(.rodata.digest_slots)
    */appldr/src/auth_data.o(.rodata.sig_sizes)
    */lv1ldr/src/auth_check.o(.rodata.cst16)
    */appldr/src/auth_data.o(.rodata.control_digest)
    */lv1ldr/zlib/lv1ldr_inflate.o(.rodata .rodata.*)
    */lv1ldr/zlib/inflate.o(.rodata .rodata.*)
    */lv1ldr/zlib/inffast.o(.rodata .rodata.*)
    */lv1ldr/zlib/inftrees.o(.rodata .rodata.*)
    */lv0ldr/src/util/shuffle_table.o(.rodata .rodata.*)
    *(.rodata .rodata.* .gnu.linkonce.r.*)
  }

  . = ALIGN(0x80) + (. & (0x80 - 1));
  .data :
  {
    */appldr/src/loader_data.o(.data.g_keyset_key)
    */appldr/src/loader_data.o(.data.g_keyset_iv)
    */appldr/src/loader_data.o(.data.g_keysets_a)
    */appldr/src/loader_data.o(.data.g_keysets_b)
    */appldr/src/loader_data.o(.data.g_keysets_7)
    */appldr/src/loader_data.o(.data.g_keysets2_a)
    */appldr/src/loader_data.o(.data.g_keysets2_b)
    */appldr/src/loader_data.o(.data.g_revoked_digest)
    */isoldr/src/qa_flag_data.o(.data.qa_flag_hmac_key)
    */isoldr/src/qa_flag_data.o(.data.qa_flag_key)
    */isoldr/src/qa_flag_data.o(.data.qa_flag_iv)
    */isoldr/src/qa_flag_data.o(.data.qa_flag_curve)
    */lv1ldr/src/auth_transfer.o(.data.g_inf_end)
    */appldr/src/decryptor_data.o(.data.g_keys_a)
    */appldr/src/decryptor_data.o(.data.g_keys_b)
    *(.data .data.* .gnu.linkonce.d.*)
  }
  .ctors : { KEEP(*(.ctors)) __CTOR_END__ = .; }
  .dtors : { KEEP(*(.dtors)) }

  /DISCARD/ : { *(.comment) *(.note*) *(.eh_frame) }
}
